# RZN2H register map
Vendor: Renesas Electronics Corporation; Series: RZN; File version: 1.00.00
CPU: other r0p0, little endian, MPU, no FPU, VTOR, 4 interrupt priority bits, 624 interrupts
Registers are 32-bit, read-write, reset 0x0 unless marked. A register's access mark holds for its fields unless they carry their own. Offsets are from the block's base; [hi:lo] are bit positions; {n}, {i} and the like mark numbered series; 'fields as' and 'values as' point back to an identical list.

## USBF — USB 2.0 Host and Function Module
Base 0x92041000
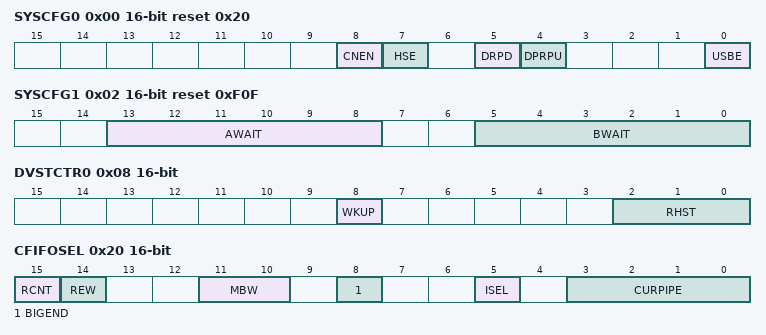
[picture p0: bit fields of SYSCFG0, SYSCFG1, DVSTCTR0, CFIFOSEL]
0x00 SYSCFG0 16-bit reset 0x20 — System Configuration Control Register 0
  [8] CNEN — Single-End Receiver Operation Enable
    0=Single-end receiver operation is disabled; 1=Single-end receiver operation is enabled
  [7] HSE — High-Speed Operation Enable
    0=High-speed operation is disabled (full-speed); 1=High-speed operation is enabled (the controller detects the communication speed)
  [5] DRPD — D+/D- Line Resistor Control
  [4] DPRPU — D+ Line Resistor Control
    0=Pulling up the line is disabled; 1=Pulling up the line is enabled
  [0] USBE — USB Block Operation Enable
    0=USB block operation is disabled; 1=USB block operation is enabled
0x02 SYSCFG1 16-bit reset 0xF0F — System Configuration Control Register 1
  [13:8] AWAIT — AHB-DMA Bridge Bus Access Wait Specification
  [5:0] BWAIT — CPU Bus Access Wait Specification
0x04 SYSSTS0 16-bit ro — System Configuration Status Register
  [1:0] LNST — USB Data Line Status Monitor
0x08 DVSTCTR0 16-bit — Device State Control Register 0
  [8] WKUP — Wakeup Output
    0=Remote wakeup signal is not output; 1=Remote wakeup signal is output
  [2:0] RHST ro — Reset Handshake
0x0C TESTMODE 16-bit — USB Test Mode Register
  [3:0] UTST — Test Mode
0x14 CFIFO — FIFO Port Register
  [31:0] FIFOPORT
0x14 CFIFOL 16-bit (alternate view of CFIFO) — FIFO Port Register
0x14 CFIFOLL 8-bit (alternate view of CFIFO) — FIFO Port Register
0x16 CFIFOH 16-bit (alternate view of CFIFO) — FIFO Port Register
  [15:0] FIFOPORT
0x17 CFIFOHH 8-bit (alternate view of CFIFO) — FIFO Port Register
  [7:0] FIFOPORT
0x18 D0FIFO — FIFO Port Register
  [31:0] FIFOPORT
0x18 D0FIFOL 16-bit (alternate view of D0FIFO) — FIFO Port Register
0x18 D0FIFOLL 8-bit (alternate view of D0FIFO) — FIFO Port Register
0x1A D0FIFOH 16-bit (alternate view of D0FIFO) — FIFO Port Register
  [15:0] FIFOPORT
0x1B D0FIFOHH 8-bit (alternate view of D0FIFO) — FIFO Port Register
  [7:0] FIFOPORT
0x1C D1FIFO — FIFO Port Register
  [31:0] FIFOPORT
0x1C D1FIFOL 16-bit (alternate view of D1FIFO) — FIFO Port Register
0x1C D1FIFOLL 8-bit (alternate view of D1FIFO) — FIFO Port Register
0x1E D1FIFOH 16-bit (alternate view of D1FIFO) — FIFO Port Register
  [15:0] FIFOPORT
0x1F D1FIFOHH 8-bit (alternate view of D1FIFO) — FIFO Port Register
  [7:0] FIFOPORT
0x20 CFIFOSEL 16-bit — CFIFO Port Select Register
  [15] RCNT — Read Count Mode
    0=The DTLN bits are cleared when all of the received data has been read from the CFIFO; 1=The DTLN bits are decremented each time the received data is read from the CFIFO
  [14] REW — Buffer Pointer Rewind
    0=The buffer pointer is not rewound; 1=The buffer pointer is rewound
  [11:10] MBW — CFIFO Port Access Bit Width
    0=8 bit width; 1=16 bit width; 2=32 bit width; 3=Setting prohibited
  [8] BIGEND — FIFO Port Endian Control
    0=Little endian; 1=Big endian
  [5] ISEL — FIFO Port Access Direction when DCP is Selected
    0=Reading from the buffer memory; 1=Writing to the buffer memory
  [3:0] CURPIPE — FIFO Port Access Pipe Specification
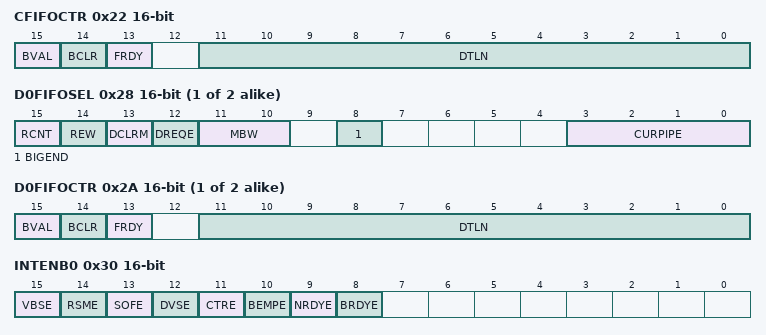
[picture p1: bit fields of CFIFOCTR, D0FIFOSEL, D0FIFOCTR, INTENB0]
0x22 CFIFOCTR 16-bit — FIFO Port Control Register
  [15] BVAL — Buffer Memory Valid Flag
    0=Invalid; 1=Writing ended
  [14] BCLR — CPU Buffer Clear
    0=Invalid; 1=Clears the CPU buffer memory on the CPU side
  [13] FRDY ro — FIFO Port Ready
    0=FIFO port is not accessible; 1=FIFO port is accessible
  [11:0] DTLN ro — Receive Data Length
{0x28+4i} D{i}FIFOSEL (i=0..1) 16-bit — D{i}FIFO Port Select Register
  [15] RCNT — Read Count Mode
    0=The DTLN bits are cleared when all of the received data has been read; 1=The DTLN bits are decremented each time the received data is read
  [14] REW — Buffer Pointer Rewind
    values as CFIFOSEL.REW
  [13] DCLRM — Auto Buffer Memory Clear Mode after Specified Pipe Data is Read
    0=Auto buffer clear mode is disabled; 1=Auto buffer clear mode is enabled
  [12] DREQE — DMA Request Enable
    0=DMA request is disabled; 1=DMA request is enabled
  [11:10] MBW — FIFO Port Access Bit Width
    values as CFIFOSEL.MBW
  [8] BIGEND — FIFO Port Endian Control
    0=Little endian; 1=Big endian
  [3:0] CURPIPE — FIFO Port Access Pipe Specification
{0x2A+4i} D{i}FIFOCTR (i=0..1) 16-bit — FIFO Port Control Register
  fields as CFIFOCTR
0x30 INTENB0 16-bit — Interrupt Enable Register 0
  [all] fields
    0=Interrupt output disabled; 1=Interrupt output enabled
  [15] VBSE — VBUS Interrupt Enable
  [14] RSME — Resume Interrupt Enable
  [13] SOFE — Frame Number Update Interrupt Enable
  [12] DVSE — Device State Transition Interrupt Enable
  [11] CTRE — Control Transfer Stage Transition Interrupt Enable
  [10] BEMPE — Buffer Empty Interrupt Enable
  [9] NRDYE — Buffer Not Ready Response Interrupt Enable
  [8] BRDYE — Buffer Ready Interrupt Enable
0x32 INTENB1 16-bit — Interrupt Enable Register 1
  [0] PDDETINTE — PDDETINT Detection Interrupt Enable
    0=Interrupt output disabled; 1=Interrupt output enabled
0x36 BRDYENB 16-bit — BRDY Interrupt Enable Register
  [9:0] PIPEBRDYE — BRDY Interrupt Enable for Each Pipe
    0=Interrupt output disabled; 1=Interrupt output enabled
0x38 NRDYENB 16-bit — NRDY Interrupt Enable Register
  [9:0] PIPENRDYE — NRDY Interrupt Enable for Each Pipe
    0=Interrupt output disabled; 1=Interrupt output enabled
0x3A BEMPENB 16-bit — BEMP Interrupt Enable Register
  [9:0] PIPEBEMPE — BEMP Interrupt Enable for Each Pipe
    0=Interrupt output disabled; 1=Interrupt output enabled
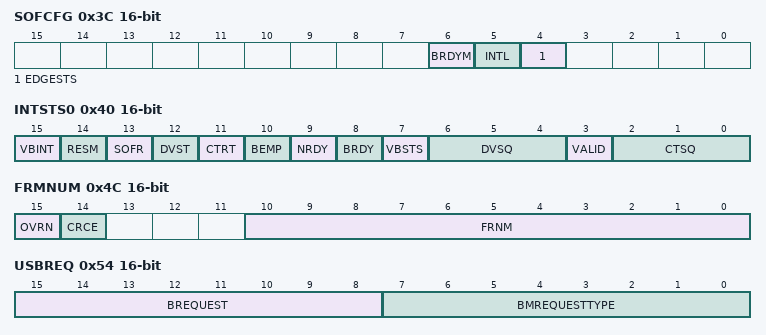
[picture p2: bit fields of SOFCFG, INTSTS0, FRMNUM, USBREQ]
0x3C SOFCFG 16-bit — SOF Pin Configuration Register
  [6] BRDYM — PIPEBRDY Interrupt Status Clear Timing
    0=Software clears the state; 1=Hardware clears the state by reading from the FIFO buffer or by writing to the FIFO buffer
  [5] INTL — Interrupt Output Sense Select
    0=Edge sense; 1=Level sense
  [4] EDGESTS ro — Interrupt Edge Processing Status
    0=Processing in response to an edge-sensed interrupt is not in progress; 1=Processing in response to an edge-sensed interrupt is in progress
0x40 INTSTS0 16-bit (reset mask 0xFF7F) — Interrupt Status Register 0
  [15] VBINT — VBUS Change Detect Interrupt Status
    0=VBUS interrupts not generated; 1=VBUS interrupts generated
  [14] RESM — Resume Interrupt Status
    0=Resume interrupts not generated; 1=Resume interrupts generated
  [13] SOFR — Frame Number Update Interrupt Status
    0=SOF interrupts not generated; 1=SOF interrupts generated
  [12] DVST — Device State Transition Interrupt Status
    0=Device state transition interrupts not generated; 1=Device state transition interrupts generated
  [11] CTRT — Control Transfer Stage Transition Interrupt Status
    0=Control transfer stage transition interrupts not generated; 1=Control transfer stage transition interrupts generated
  [10] BEMP ro — BEMP Interrupt Status
    0=BEMP interrupts not generated; 1=BEMP interrupts generated
  [9] NRDY ro — NRDY Interrupt Status
    0=NRDY interrupts not generated; 1=NRDY interrupts generated
  [8] BRDY ro — BRDY Interrupt Status
    0=BRDY interrupts not generated; 1=BRDY interrupts generated
  [7] VBSTS ro — VBUS Input Status
    0=USB_VUBUSIN pin is at the low level; 1=USB_VUBUSIN pin is at the high level
  [6:4] DVSQ ro — Device State
    0=Powered state; 1=Default state; 2=Address state; 3=Configured state; 0b1xx=Suspended state
  [3] VALID — USB Request Reception
    0=Not detected; 1=Setup packet reception
  [2:0] CTSQ ro — Control Transfer Stage
    0=Idle or setup stage; 1=Control read data stage; 2=Control read status stage; 3=Control write data stage; 4=Control write status stage; 5=Control write (no data) status stage; 6=Control transfer sequence error
0x42 INTSTS1 16-bit — Interrupt Status Register 1
  [0] PDDETINT — PDDET Detection Interrupt Status
    0=PDDET interrupts not generated; 1=PDDET interrupts generated
0x46 BRDYSTS 16-bit — BRDY Interrupt Status Register
  [9:0] PIPEBRDY — BRDY Interrupt Status for Each Pipe
    0=Interrupts not generated; 1=Interrupts generated
0x48 NRDYSTS 16-bit — NRDY Interrupt Status Register
  [9:0] PIPENRDY — NRDY Interrupt Status for Each Pipe
    0=Interrupts not generated; 1=Interrupts generated
0x4A BEMPSTS 16-bit — BEMP Interrupt Status Register
  [9:0] PIPEBEMP — BEMP Interrupt Status for Each Pipe
    0=Interrupts not generated; 1=Interrupts generated
0x4C FRMNUM 16-bit — Frame Number Register
  [15] OVRN — Overrun/Underrun Detection Status
    0=No error; 1=An error occurred
  [14] CRCE — CRC Error Detection Status
    0=No error; 1=An error occurred
  [10:0] FRNM ro — Frame Number
0x4E UFRMNUM 16-bit ro — Frame Number Register
  [2:0] UFRNM — Microframe Number
0x50 USBADDR 16-bit ro — USB Address Register
  [6:0] USBADDR — USB Address
0x54 USBREQ 16-bit ro — USB Request Type Register
  [15:8] BREQUEST — Request
  [7:0] BMREQUESTTYPE — Request Type
0x56 USBVAL 16-bit ro — USB Request Value Register
  [15:0] WVALUE — Value
0x58 USBINDX 16-bit ro — USB Request Index Register
  [15:0] WINDEX — Index
0x5A USBLENG 16-bit ro — USB Request Length Register
  [15:0] WLENGTH — Length
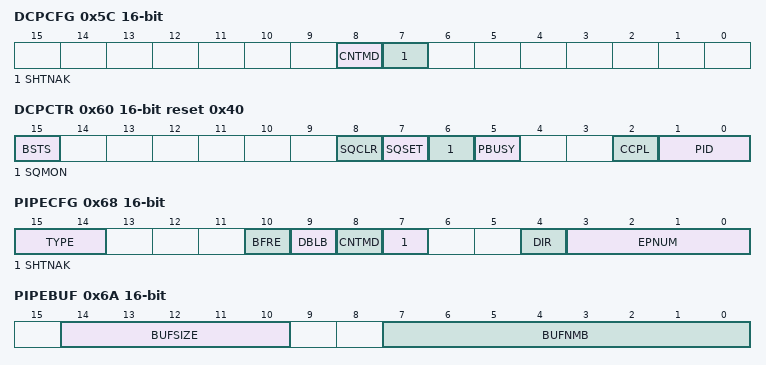
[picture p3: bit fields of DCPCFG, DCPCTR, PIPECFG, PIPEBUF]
0x5C DCPCFG 16-bit — DCP Configuration Register
  [8] CNTMD — Continuous Transfer Mode
    0=Continuous transfer mode disabled; 1=Continuous transfer mode enabled
  [7] SHTNAK — Disabling PIPE at the End of Transfer
    0=The pipe continues at the end of transfer; 1=The pipe is disabled at the end of transfer
0x5E DCPMAXP 16-bit reset 0x40 — DCP Maximum Packet Size Register
  [6:0] MXPS — Maximum Packet Size
0x60 DCPCTR 16-bit reset 0x40 — DCP Control Register
  [15] BSTS ro — Buffer Status
    0=Buffer access disabled; 1=Buffer access enabled
  [8] SQCLR — Toggle Bit Clear
    0=Writing has no effect; 1=Specifies DATA0
  [7] SQSET — Toggle Bit Set
    0=Writing has no effect; 1=Specifies DATA1
  [6] SQMON ro — Sequence Toggle Bit Monitor
    0=DATA0; 1=DATA1
  [5] PBUSY ro — PIPE Busy
    0=The pipe is not being used by the USB bus; 1=The pipe is being used by the USB bus
  [2] CCPL — Control Transfer End Enable
    0=End of the control transfer disabled; 1=End of the control transfer enabled
  [1:0] PID — Response PID
    0=NAK response; 1=BUF response (depending on the buffer state); 2=STALL response; 3=STALL response
0x64 PIPESEL 16-bit — Pipe Window Select Register
  [3:0] PIPESEL — Pipe Window Select
    0=No pipe selected; {v}=Pipe {v} (v=1..9); other=Others (Reserved)
0x68 PIPECFG 16-bit — Pipe Configuration Register
  [15:14] TYPE — Transfer Type
    0=Pipe is not in use; 1=Bulk transfer; 2=Interrupt transfer; 3=Isochronous transfer
  [10] BFRE — BRDY Interrupt Operation Specification
    0=BRDY interrupt notification upon transmitting or receiving data; 1=BRDY interrupt notification upon reading data
  [9] DBLB — Double Buffer Mode
    0=Single-buffer operation; 1=Double-buffer operation
  [8] CNTMD — Continuous Transfer Mode
    0=Non-continuous transfer mode; 1=Continuous transfer mode
  [7] SHTNAK — Pipe Disable at the End of Transfer
    0=Pipe continued at end of transfer; 1=Pipe disabled at end of transfer
  [4] DIR — Transfer Direction
    0=Receiving direction; 1=Transmitting direction
  [3:0] EPNUM — Endpoint Number
0x6A PIPEBUF 16-bit — Pipe Buffer Specification Register
  [14:10] BUFSIZE — Buffer size
  [7:0] BUFNMB — Buffer number
0x6C PIPEMAXP 16-bit — Pipe Maximum Packet Size Register
  [10:0] MXPS — Maximum Packet Size
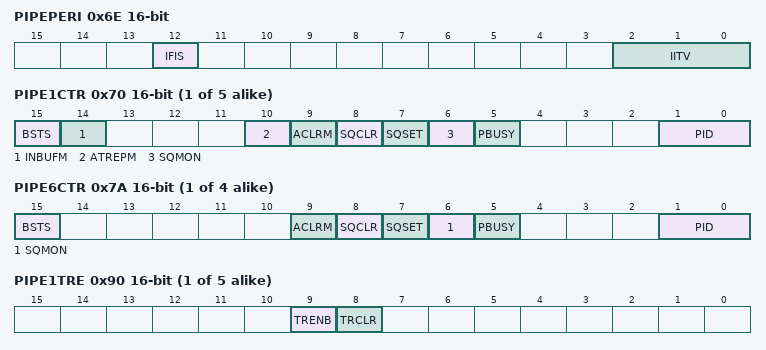
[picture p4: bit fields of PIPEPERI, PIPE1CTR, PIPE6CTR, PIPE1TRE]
0x6E PIPEPERI 16-bit — Pipe Timing Control Register
  [12] IFIS — Isochronous IN Buffer Flush
    0=The buffer is not flushed; 1=The buffer is flushed
  [2:0] IITV — Interval Error Detection Spacing
{0x6E+2i} PIPE{i}CTR (i=1..5) 16-bit — PIPE{i} Control Register
  [15] BSTS ro — Buffer Status
    0=Buffer access is disabled; 1=Buffer access is enabled
  [14] INBUFM ro — Transfer Buffer Monitor
    0=FIFO buffer contains no transmittable data; 1=FIFO buffer contains transmittable data
  [10] ATREPM — Auto Response Mode
    0=Disabled; 1=Enabled (a zero-length packet response while sending, NAK response and an NRDY interrupt is issued while receiving)
  [9] ACLRM — Auto Buffer Clear Mode
    0=Disabled; 1=Enabled (all buffers are initialized)
  [8] SQCLR — Toggle Bit Clear
    0=Writing has no effect; 1=Specifies DATA0
  [7] SQSET — Toggle Bit Set
    0=Writing has no effect; 1=Specifies DATA1
  [6] SQMON ro — Toggle Bit Confirm
    0=DATA0; 1=DATA1
  [5] PBUSY ro — PIPE Busy
    0=The pipe is not being currently used for the USB bus; 1=The pipe is being currently used for the USB bus
  [1:0] PID — Response PID
    values as DCPCTR.PID
{0x6E+2i} PIPE{i}CTR (i=6..9) 16-bit — PIPE{i} Control Register
  [15] BSTS ro — Buffer Status
    0=Buffer access is disabled; 1=Buffer access is enabled
  [9] ACLRM — Auto Buffer Clear Mode
    0=Disabled; 1=Enabled (all buffers are initialized)
  [8] SQCLR — Toggle Bit Clear
    0=Writing has no effect; 1=Specifies DATA0
  [7] SQSET — Toggle Bit Set
    0=Writing has no effect; 1=Specifies DATA1
  [6] SQMON ro — Toggle Bit Confirm
    0=DATA0; 1=DATA1
  [5] PBUSY ro — PIPE Busy
    values as PIPE1CTR.PBUSY
  [1:0] PID — Response PID
    values as DCPCTR.PID
{0x8C+4i} PIPE{i}TRE (i=1..5) 16-bit — PIPE{i} Transaction Counter Enable Register
  [9] TRENB — Transaction Counter Enable
    0=The transaction counter is disabled; 1=The transaction counter is enabled
  [8] TRCLR — Transaction Counter Clear
    0=Invalid; 1=The current counter value is cleared
{0x8E+4i} PIPE{i}TRN (i=1..5) 16-bit — PIPE{i} Transaction Counter Register
  [15:0] TRNCNT — Transaction Counter
0x102 LPSTS 16-bit — Low Power Status Register
  [14] SUSPM — UTMI SuspendM Control
    0=UTMI suspend mode; 1=UTMI normal mode
{0x400+0x40*i} N0SA_{i} (i=0..1) — Next Source Address Register {i}
  [31:0] SAWD — Source Address or Write Data
{0x404+0x40*i} N0DA_{i} (i=0..1) — Next Destination Address Register {i}
  [31:0] DA — Destination Address
{0x408+0x40*i} N0TB_{i} (i=0..1) — Next Transaction Byte Register {i}
  [31:0] TB — Transaction Byte
{0x40C+0x40*i} N1SA_{i} (i=0..1) — Next Source Address Register {i}
  [31:0] SAWD — Source Address or Write Data
{0x410+0x40*i} N1DA_{i} (i=0..1) — Next Destination Address Register {i}
  [31:0] DA — Destination Address
{0x414+0x40*i} N1TB_{i} (i=0..1) — Next Transaction Byte Register {i}
  [31:0] TB — Transaction Byte
{0x418+0x40*i} CRSA_{i} (i=0..1) ro — Current Source Address Register {i}
  [31:0] CRSA — Source Address
{0x41C+0x40*i} CRDA_{i} (i=0..1) ro — Current Destination Address Register {i}
  [31:0] CRDA — Destination Address
{0x420+0x40*i} CRTB_{i} (i=0..1) ro — Current Transaction Byte Register {i}
  [31:0] CRTB — Transaction Byte
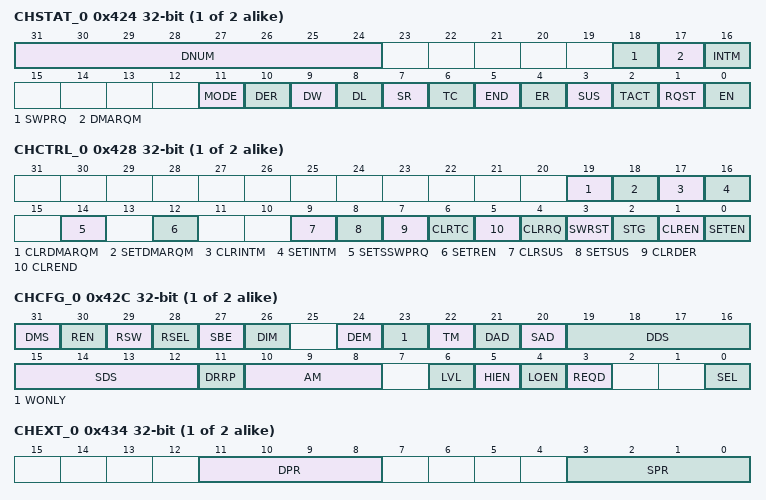
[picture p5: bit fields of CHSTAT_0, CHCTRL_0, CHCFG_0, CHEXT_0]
{0x424+0x40*i} CHSTAT_{i} (i=0..1) ro — Channel Status Register {i}
  [31:24] DNUM — Data Number
  [18] SWPRQ — Sweep Request
    0=The forced ejection request is not asserted; 1=The forced ejection request is asserted
  [17] DMARQM — DMAREQ Mask
    0=The temporary mask status is cleared; 1=In temporary mask status
  [16] INTM — Interrupt Mask
    values as DMARQM
  [11] MODE — DMA Mode
    0=Register mode; 1=Link mode
  [10] DER — Descriptor Error
    0=No descriptor error occurred; 1=A descriptor error occurred
  [9] DW — Descriptor WriteBack
    0=Other than header write-back in link mode; 1=(When ER in the CHSTAT_n register is 0) During header write-back in link mode (When ER in the CHSTAT_n register is 1) A bus error occurred during header write-back in link mode
  [8] DL — Descriptor Load
    0=Other than descriptor read; 1=(When ER = 0) While the descriptor is read in link mode (When ER = 1) A bus error occurred while the descriptor was read in link mode
  [7] SR — Selected Register Set
    0=Next0 register set; 1=Next1 register set
  [6] TC — Terminal Count
    0=DMA transfer not completed; 1=DMA transfer completed
  [5] END — USB_FDMAn Interrupted
    0=DMA transfer not completed; 1=DMA transfer completed
  [4] ER — Error
    0=No error response was received; 1=An error response was received
  [3] SUS — Suspend
    0=Channel_n is not suspended; 1=Channel_n is suspended
  [2] TACT — Transaction Active
    0=DMA of channel_n is inactive; 1=DMA of channel_n is in progress
  [1] RQST — Request
    0=No DMA transfer request has been received; 1=A DMA transfer request has been received
  [0] EN — Enable
    0=Operation disabled; 1=Operation enabled
{0x428+0x40*i} CHCTRL_{i} (i=0..1) wo — Channel Control Register {i}
  [19] CLRDMARQM — Clear DMAREQ Mask
    0=No effect; 1=Clears the mask status set by the SETDMARQM bit
  [18] SETDMARQM — SET DMAREQ Mask
    0=No effect; 1=Masks a DMA transfer request from the USB control
  [17] CLRINTM — Clear Interrupt Mask
    0=No effect; 1=Clears the mask status set by the SETINTM bit
  [16] SETINTM — Set Interrupt Mask
    0=No effect; 1=Masks USB_FDMAn
  [14] SETSSWPRQ — Set Software Sweep Request
    0=No effect; 1=Writes the buffer data (that has not been written to the transfer destination) to the transfer destination
  [12] SETREN — Set Register Set Enable
    0=No effect; 1=Sets the REN bit in the CHCFG_n register to 1
  [9] CLRSUS — Clear Suspend
    0=No effect; 1=Clears the suspended status of the ongoing DMA transfer
  [8] SETSUS — Set Suspend
    0=No effect; 1=Suspends the ongoing DMA transfer
  [7] CLRDER — Clear DER
    0=No effect; 1=Clears the DER bit in the CHSTAT_n register
  [6] CLRTC — Clear TC
    0=No effect; 1=Clears the TC bit in the CHSTAT_n register
  [5] CLREND — Clear End
    0=No effect; 1=Clears the END bit in the CHSTAT_n register
  [4] CLRRQ — Clear Request
    0=No effect; 1=Clears the RQST bit in the CHSTAT_n register
  [3] SWRST — Software Reset
    0=No effect; 1=Clears each bit in the CHSTAT_n register
  [2] STG — Software Trigger
    0=No effect; 1=A transfer request is set by software. (The RQST bit in the CHSTAT_n register is set)
  [1] CLREN — Clear Enable
    0=No effect; 1=DMA transfer is disabled. (The EN bit in the CHSTAT_n register is cleared)
  [0] SETEN — Set Enable
    0=No effect; 1=DMA transfer is enabled. (The EN bit in the CHSTAT_n register is set)
{0x42C+0x40*i} CHCFG_{i} (i=0..1) — Channel Configuration Register {i}
  [31] DMS — DMA Mode Select
    0=Register mode (initial value); 1=Link mode
  [30] REN — Register Set Enable
    0=Does not perform DMA transaction continuously; 1=Performs DMA transaction continuously
  [29] RSW — Register Select Switch
    0=Does not reverse the RSEL bit upon completion of a DMA transaction (initial value); 1=Reverses the RSEL bit upon completion of a DMA transaction
  [28] RSEL — Register Set Select
    0=Executes Next0 register set (initial value); 1=Executes Next1 register set
  [27] SBE — Sweep Buffer Enable
    0=Does not sweep buffer data and aborts the transfer (initial value); 1=Sweeps buffer data and aborts the transfer
  [26] DIM — Descriptor Interrupt Mask
    0=Does not mask USB_FDMAn (initial value); 1=Masks USB_FDMAn
  [24] DEM — USB_FDMAn Mask
    0=Does not mask USB_FDMAn interrupt detection (initial value); 1=Masks USB_FDMAn interrupt detection
  [23] WONLY — Write Only Mode
    0=Normal operation (initial value); 1=Write-only mode
  [22] TM — Sets the transfer request signal between the USB control and the DMAC.
  [21] DAD — Destination Address Direction
    0=Increment (initial value); 1=Fixed
  [20] SAD — Source Address Direction
    0=Increment (initial value); 1=Fixed
  [19:16] DDS — Destination Data Size
    0=8 bits (initial value); 1=16 bits; 2=32 bits; 3=64 bits; 4=128 bits; 5=256 bits; 6=512 bits; 7=1024 bits
  [15:12] SDS — Source Data Size
    values as DDS
  [11] DRRP — Descriptor Read Repeat
    0=Sets the DER bit in the CHSTAT_n register to stop operation (initial value); 1=Reads the same descriptor continuously until LV becomes 1. When LV = 1, DMA transfer using the descriptor value starts. The descriptor read interval is controlled by the DSCITVL register.
  [10:8] AM — These bits set the transfer request signal between the USB control and the DMAC.
  [6] LVL — Sets the transfer request signal between the USB control and the DMAC.
  [5] HIEN — Sets the transfer request signal between the USB control and the DMAC.
  [4] LOEN — Sets the transfer request signal between the USB control and the DMAC.
  [3] REQD — Request Direction
    0=The USB control side is source (initial value); 1=The USB control side is destination
  [0] SEL — Terminal Select
    0=D0FIFO is used; 1=D1FIFO is used
{0x430+0x40*i} CHITVL_{i} (i=0..1) — Channel Interval Register {i}
  [15:0] ITVL — Interval
{0x434+0x40*i} CHEXT_{i} (i=0..1) — Channel Extension Register {i}
  [11:8] DPR — Destination PROT
  [3:0] SPR — Source PROT
{0x438+0x40*i} NXLA_{i} (i=0..1) — Next Link Address Register {i}
  [31:0] NXLA — Next Link Address
{0x43C+0x40*i} CRLA_{i} (i=0..1) ro — Current Link Address Register {i}
  [31:0] CRLA — Current Link Address
{0x600+0x20*i} SCNT_{i} (i=0..1) — Source Continuous Register {i}
  [31:0] SCNT — Source Continuous
{0x604+0x20*i} SSKP_{i} (i=0..1) — Source Skip Register {i}
  [31:0] SSKP — Source Skip
{0x608+0x20*i} DCNT_{i} (i=0..1) — Destination Continuous Register {i}
  [31:0] DCNT — Destination Continuous
{0x60C+0x20*i} DSKP_{i} (i=0..1) — Destination Skip Register {i}
  [31:0] DSKP — Destination Skip
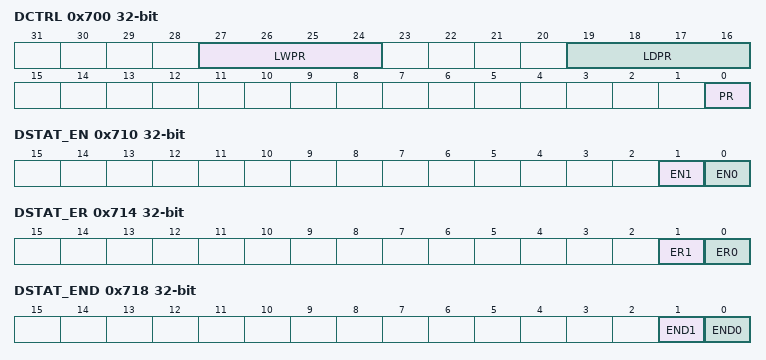
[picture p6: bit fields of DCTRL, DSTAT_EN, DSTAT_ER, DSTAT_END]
0x700 DCTRL — DMA Control Register
  [27:24] LWPR — Link WriteBack PROT
  [19:16] LDPR — Link Descriptor PROT
  [0] PR — Priority
    0=Fixed priority mode; 1=Round-robin mode
0x704 DSCITVL — Descriptor Interval Register
  [15:8] DITVL — Descriptor Interval
0x710 DSTAT_EN ro — DMA Status EN Register
  [1] EN1 — Channel 1 EN
  [0] EN0 — Channel 0 EN
0x714 DSTAT_ER ro — DMA Status ER Register
  [1] ER1 — Channel 1 ER
  [0] ER0 — Channel 0 ER
0x718 DSTAT_END ro — DMA Status END Register
  [1] END1 — Channel 1 END
  [0] END0 — Channel 0 END
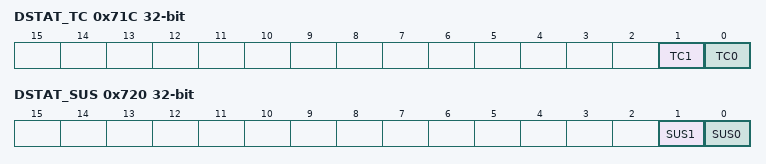
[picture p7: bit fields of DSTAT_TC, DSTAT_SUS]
0x71C DSTAT_TC ro — DMA Status TC Register
  [1] TC1 — Channel 1 TC
  [0] TC0 — Channel 0 TC
0x720 DSTAT_SUS ro — DMA Status SUS Register
  [1] SUS1 — Channel 1 SUS
  [0] SUS0 — Channel 0 SUS
